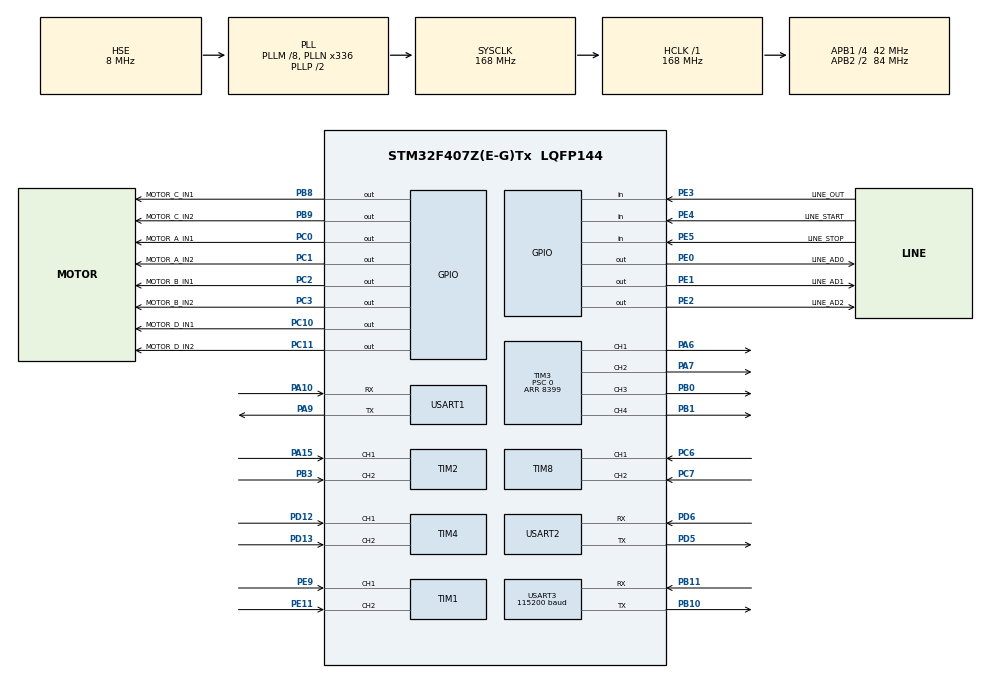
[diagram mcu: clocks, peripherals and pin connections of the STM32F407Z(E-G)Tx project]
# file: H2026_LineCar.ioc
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FREERTOS.Tasks01=controlTask,40,1024,StartControlTask,Default,NULL,Dynamic,NULL,NULL;feedbackTask,24,768,StartFeedbackTask,Default,NULL,Dynamic,NULL,NULL;imuTask,32,512,StartImuTask,Default,NULL,Dynamic,NULL,NULL
FREERTOS.configTOTAL_HEAP_SIZE=32768
FREERTOS.configUSE_NEWLIB_REENTRANT=1
Mcu.Family=STM32F4
Mcu.Name=STM32F407Z(E-G)Tx
Mcu.Package=LQFP144
NVIC.PriorityGroup=NVIC_PRIORITYGROUP_4
NVIC.TIM6_DAC_IRQn=true\:15\:0\:false\:false\:true\:false\:false\:true\:true
NVIC.TIM7_IRQn=true\:5\:0\:false\:false\:true\:true\:true\:true\:true
NVIC.TimeBase=TIM6_DAC_IRQn
NVIC.TimeBaseIP=TIM6
NVIC.USART1_IRQn=true\:6\:0\:true\:false\:true\:true\:true\:true\:true
NVIC.USART2_IRQn=true\:6\:0\:true\:false\:true\:true\:true\:true\:true
PA10.Mode=Asynchronous
PA10.Signal=USART1_RX
PA13.Mode=Serial_Wire
PA13.Signal=SYS_JTMS-SWDIO
PA14.Mode=Serial_Wire
PA14.Signal=SYS_JTCK-SWCLK
PA15.Signal=S_TIM2_CH1_ETR
PA6.Signal=S_TIM3_CH1
PA7.Signal=S_TIM3_CH2
PA9.Mode=Asynchronous
PA9.Signal=USART1_TX
PB0.Signal=S_TIM3_CH3
PB1.Signal=S_TIM3_CH4
PB3.Signal=S_TIM2_CH2
PB8.GPIO_Label=MOTOR_C_IN1
PB8.Signal=GPIO_Output
PB9.GPIO_Label=MOTOR_C_IN2
PB9.Signal=GPIO_Output
PC0.GPIO_Label=MOTOR_A_IN1
PC0.Signal=GPIO_Output
PC1.GPIO_Label=MOTOR_A_IN2
PC1.Signal=GPIO_Output
PC10.GPIO_Label=MOTOR_D_IN1
PC10.Signal=GPIO_Output
PC11.GPIO_Label=MOTOR_D_IN2
PC11.Signal=GPIO_Output
PC2.GPIO_Label=MOTOR_B_IN1
PC2.Signal=GPIO_Output
PC3.GPIO_Label=MOTOR_B_IN2
PC3.Signal=GPIO_Output
PC6.Signal=S_TIM8_CH1
PC7.Signal=S_TIM8_CH2
PD12.Signal=S_TIM4_CH1
PD13.Signal=S_TIM4_CH2
PD5.Mode=Asynchronous
PD5.Signal=USART2_TX
PD6.Mode=Asynchronous
PD6.Signal=USART2_RX
PE11.Signal=S_TIM1_CH2
PE9.Signal=S_TIM1_CH1
PH0-OSC_IN.Mode=HSE-External-Oscillator
PH0-OSC_IN.Signal=RCC_OSC_IN
PH1-OSC_OUT.Mode=HSE-External-Oscillator
PH1-OSC_OUT.Signal=RCC_OSC_OUT
ProjectManager.HeapSize=0x1000
ProjectManager.StackSize=0x1000
ProjectManager.TargetToolchain=STM32CubeIDE
RCC.48MHZClocksFreq_Value=84000000
RCC.AHBFreq_Value=168000000
RCC.APB1CLKDivider=RCC_HCLK_DIV4
RCC.APB1Freq_Value=42000000
RCC.APB1TimFreq_Value=84000000
RCC.APB2CLKDivider=RCC_HCLK_DIV2
RCC.APB2Freq_Value=84000000
RCC.APB2TimFreq_Value=168000000
RCC.CortexFreq_Value=168000000
RCC.HCLKFreq_Value=168000000
RCC.HSE_VALUE=8000000
RCC.HSI_VALUE=16000000
RCC.LSE_VALUE=32768
RCC.PLLM=8
RCC.PLLN=336
RCC.PLLSourceVirtual=RCC_PLLSOURCE_HSE
RCC.SYSCLKFreq_VALUE=168000000
RCC.SYSCLKSource=RCC_SYSCLKSOURCE_PLLCLK
RCC.VCOOutputFreq_Value=336000000
SH.S_TIM1_CH1.0=TIM1_CH1,Encoder_Interface
SH.S_TIM1_CH2.0=TIM1_CH2,Encoder_Interface
SH.S_TIM2_CH1_ETR.0=TIM2_CH1,Encoder_Interface
SH.S_TIM2_CH2.0=TIM2_CH2,Encoder_Interface
SH.S_TIM3_CH1.0=TIM3_CH1,PWM Generation1 CH1
SH.S_TIM3_CH2.0=TIM3_CH2,PWM Generation2 CH2
SH.S_TIM3_CH3.0=TIM3_CH3,PWM Generation3 CH3
SH.S_TIM3_CH4.0=TIM3_CH4,PWM Generation4 CH4
SH.S_TIM4_CH1.0=TIM4_CH1,Encoder_Interface
SH.S_TIM4_CH2.0=TIM4_CH2,Encoder_Interface
SH.S_TIM8_CH1.0=TIM8_CH1,Encoder_Interface
SH.S_TIM8_CH2.0=TIM8_CH2,Encoder_Interface
TIM1.EncoderMode=TIM_ENCODERMODE_TI12
TIM1.IC1Filter=10
TIM1.IC2Filter=10
TIM2.EncoderMode=TIM_ENCODERMODE_TI12
TIM2.IC1Filter=10
TIM2.IC2Filter=10
TIM3.AutoReloadPreload=TIM_AUTORELOAD_PRELOAD_ENABLE
TIM3.Channel-PWM\ Generation1\ CH1=TIM_CHANNEL_1
TIM3.Channel-PWM\ Generation2\ CH2=TIM_CHANNEL_2
TIM3.Channel-PWM\ Generation3\ CH3=TIM_CHANNEL_3
TIM3.Channel-PWM\ Generation4\ CH4=TIM_CHANNEL_4
TIM3.Period=8399
TIM3.Prescaler=0
TIM4.EncoderMode=TIM_ENCODERMODE_TI12
TIM4.IC1Filter=10
TIM4.IC2Filter=10
TIM7.Period=99
TIM7.Prescaler=8399
TIM8.EncoderMode=TIM_ENCODERMODE_TI12
TIM8.IC1Filter=10
TIM8.IC2Filter=10
USART1.VirtualMode=VM_ASYNC
USART2.VirtualMode=VM_ASYNC
VP_FREERTOS_VS_CMSIS_V2.Mode=CMSIS_V2
VP_SYS_VS_tim6.Mode=TIM6
VP_TIM3_VS_ClockSourceINT.Mode=Internal
VP_TIM7_VS_ClockSourceINT.Mode=Enable_Timer
board=custom
PB10.Mode=Asynchronous
PB10.Signal=USART3_TX
PB11.Mode=Asynchronous
PB11.Signal=USART3_RX
PB10.GPIO_PuPd=GPIO_PULLUP
PB11.GPIO_PuPd=GPIO_PULLUP
USART3.BaudRate=115200
USART3.VirtualMode=VM_ASYNC
Dma.Request0=USART3_RX
Dma.USART3_RX.0.Instance=DMA1_Stream1
Dma.USART3_RX.0.Direction=DMA_PERIPH_TO_MEMORY
Dma.USART3_RX.0.PeriphInc=DMA_PINC_DISABLE
Dma.USART3_RX.0.MemInc=DMA_MINC_ENABLE
Dma.USART3_RX.0.PeriphDataAlignment=DMA_PDATAALIGN_BYTE
Dma.USART3_RX.0.MemDataAlignment=DMA_MDATAALIGN_BYTE
Dma.USART3_RX.0.Mode=DMA_CIRCULAR
Dma.USART3_RX.0.Priority=DMA_PRIORITY_HIGH
Dma.USART3_RX.0.FIFOMode=DMA_FIFOMODE_DISABLE
NVIC.USART3_IRQn=true\:6\:0\:true\:false\:true\:true\:true\:true\:true
NVIC.DMA1_Stream1_IRQn=true\:6\:0\:true\:false\:true\:false\:true\:true\:true
PE0.GPIO_Label=LINE_AD0
PE0.Signal=GPIO_Output
PE1.GPIO_Label=LINE_AD1
PE1.Signal=GPIO_Output
PE2.GPIO_Label=LINE_AD2
PE2.Signal=GPIO_Output
PE3.GPIO_Label=LINE_OUT
PE3.Signal=GPIO_Input
PE4.GPIO_Label=LINE_START
PE4.Signal=GPIO_Input
PE4.GPIO_PuPd=GPIO_PULLUP
PE5.GPIO_Label=LINE_STOP
PE5.Signal=GPIO_Input
PE5.GPIO_PuPd=GPIO_PULLUP

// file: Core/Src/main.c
/* USER CODE BEGIN Header */
/**
  ******************************************************************************
  * @file           : main.c
  * @brief          : Main program body
  ******************************************************************************
  * @attention
  *
  * Copyright (c) 2026 STMicroelectronics.
  * All rights reserved.
  *
  * This software is licensed under terms that can be found in the LICENSE file
  * in the root directory of this software component.
  * If no LICENSE file comes with this software, it is provided AS-IS.
  *
  ******************************************************************************
  */
/* USER CODE END Header */
#include "main.h"
#include "cmsis_os.h"
#include "tim.h"
#include "usart.h"
#include "gpio.h"

/* USER CODE BEGIN Includes */
#include "chassis_control.h"

/* USER CODE END Includes */

void SystemClock_Config(void);
void MX_FREERTOS_Init(void);

int main(void)
{

  /* MCU Configuration--------------------------------------------------------*/

  /* Reset of all peripherals, Initializes the Flash interface and the Systick. */
  HAL_Init();

  /* Configure the system clock */
  SystemClock_Config();

  /* Initialize all configured peripherals */
  MX_GPIO_Init();
  MX_TIM3_Init();
  MX_USART1_UART_Init();
  MX_TIM1_Init();
  MX_TIM2_Init();
  MX_TIM4_Init();
  MX_TIM7_Init();
  MX_TIM8_Init();
  MX_USART2_UART_Init();
  MX_USART3_UART_Init();

  /* Init scheduler */
  osKernelInitialize();  /* Call init function for freertos objects (in cmsis_os2.c) */
  MX_FREERTOS_Init();

  /* Start scheduler */
  osKernelStart();

  /* We should never get here as control is now taken by the scheduler */

  /* Infinite loop */
  while (1)
  {

  }
}

void SystemClock_Config(void)
{
  RCC_OscInitTypeDef RCC_OscInitStruct = {0};
  RCC_ClkInitTypeDef RCC_ClkInitStruct = {0};

  /** Configure the main internal regulator output voltage
  */
  __HAL_RCC_PWR_CLK_ENABLE();
  __HAL_PWR_VOLTAGESCALING_CONFIG(PWR_REGULATOR_VOLTAGE_SCALE1);

  /** Initializes the RCC Oscillators according to the specified parameters
  * in the RCC_OscInitTypeDef structure.
  */
  RCC_OscInitStruct.OscillatorType = RCC_OSCILLATORTYPE_HSE;
  RCC_OscInitStruct.HSEState = RCC_HSE_ON;
  RCC_OscInitStruct.PLL.PLLState = RCC_PLL_ON;
  RCC_OscInitStruct.PLL.PLLSource = RCC_PLLSOURCE_HSE;
  RCC_OscInitStruct.PLL.PLLM = 8;
  RCC_OscInitStruct.PLL.PLLN = 336;
  RCC_OscInitStruct.PLL.PLLP = RCC_PLLP_DIV2;
  RCC_OscInitStruct.PLL.PLLQ = 4;
  if (HAL_RCC_OscConfig(&RCC_OscInitStruct) != HAL_OK)
  {
    Error_Handler();
  }

  /** Initializes the CPU, AHB and APB buses clocks
  */
  RCC_ClkInitStruct.ClockType = RCC_CLOCKTYPE_HCLK|RCC_CLOCKTYPE_SYSCLK
                              |RCC_CLOCKTYPE_PCLK1|RCC_CLOCKTYPE_PCLK2;
  RCC_ClkInitStruct.SYSCLKSource = RCC_SYSCLKSOURCE_PLLCLK;
  RCC_ClkInitStruct.AHBCLKDivider = RCC_SYSCLK_DIV1;
  RCC_ClkInitStruct.APB1CLKDivider = RCC_HCLK_DIV4;
  RCC_ClkInitStruct.APB2CLKDivider = RCC_HCLK_DIV2;

  if (HAL_RCC_ClockConfig(&RCC_ClkInitStruct, FLASH_LATENCY_5) != HAL_OK)
  {
    Error_Handler();
  }
}

void HAL_TIM_PeriodElapsedCallback(TIM_HandleTypeDef *htim)
{
  if (htim->Instance == TIM6)
  {
    HAL_IncTick();
  }
  /* USER CODE BEGIN Callback 1 */

  if (htim->Instance == TIM7)
  {
    Chassis_ControlPeriodElapsedCallback();
  }

  /* USER CODE END Callback 1 */
}

void Error_Handler(void)
{
  __disable_irq();
  while (1)
  {
  }
}

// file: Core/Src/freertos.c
/* H2026 line-following application. The control task exclusively owns motion. */
#include "FreeRTOS.h"
#include "task.h"
#include "main.h"
#include "cmsis_os.h"
#include "chassis_control.h"
#include "line_app.h"
#include "encoder.h"
#include "control_timing.h"
#include "runtime_diagnostics.h"
#include "jy901s.h"
#include "Vofa.h"

#define CONTROL_FLAG_ENCODER_SAMPLE (1UL << 0)
RuntimeDiagnostics g_runtime_diagnostics;
static Vofa_HandleTypedef s_vofa;
osThreadId_t controlTaskHandle, feedbackTaskHandle, imuTaskHandle;
static void StartControlTask(void *argument);
static void StartFeedbackTask(void *argument);
static void StartImuTask(void *argument);
static const osThreadAttr_t control_attributes={.name="controlTask",.stack_size=4096,.priority=osPriorityHigh};
static const osThreadAttr_t feedback_attributes={.name="feedbackTask",.stack_size=3072,.priority=osPriorityNormal};
static const osThreadAttr_t imu_attributes={.name="imuTask",.stack_size=2048,.priority=osPriorityAboveNormal};

void MX_FREERTOS_Init(void)
{
  Vofa_Init(&s_vofa,VOFA_MODE_SKIP);
  VofaPort_Init();
  controlTaskHandle=osThreadNew(StartControlTask,NULL,&control_attributes);
  feedbackTaskHandle=osThreadNew(StartFeedbackTask,NULL,&feedback_attributes);
  imuTaskHandle=osThreadNew(StartImuTask,NULL,&imu_attributes);
  if (!controlTaskHandle || !feedbackTaskHandle || !imuTaskHandle) Error_Handler();
}

static void StartControlTask(void *argument)
{
  (void)argument;
  ControlTiming timing={0};
  CoreDebug->DEMCR|=CoreDebug_DEMCR_TRCENA_Msk;
  DWT->CTRL|=DWT_CTRL_CYCCNTENA_Msk;
  if (Chassis_Init()!=HAL_OK) Error_Handler();
  LineApp_Init();
  for (;;) {
    uint32_t flags=osThreadFlagsWait(CONTROL_FLAG_ENCODER_SAMPLE,osFlagsWaitAny,osWaitForever);
    if ((flags & osFlagsError)!=0U) continue;
    uint32_t start=HAL_GetTick(), cycles=DWT->CYCCNT;
    ControlTimingResult result=ControlTiming_Update(&timing,g_runtime_diagnostics.control_events,start);
    if (result==CONTROL_TIMING_NONE) continue;
    g_runtime_diagnostics.max_interval_ms=timing.max_interval;
    g_runtime_diagnostics.missed_events=timing.missed_events;
    g_runtime_diagnostics.late_wakes=timing.late_wakes;
    if (result==CONTROL_TIMING_FAULT) {
      LineApp_Fault(LINE_TIMING_FAULT);
      Chassis_StopWithReason(CHASSIS_STOP_CONTROL_TIMING);
      Encoder_Reset();
    } else {
      LineApp_Step();
      Chassis_ControlStep();
      ++g_runtime_diagnostics.control_runs;
    }
    uint32_t us=(DWT->CYCCNT-cycles)/(SystemCoreClock/1000000U);
    if (us>g_runtime_diagnostics.max_execution_us) g_runtime_diagnostics.max_execution_us=us;
    uint32_t ms=HAL_GetTick()-start;
    if (ms>g_runtime_diagnostics.max_execution_ms) g_runtime_diagnostics.max_execution_ms=ms;
  }
}

static void StartFeedbackTask(void *argument)
{
  (void)argument;
  for (;;) {
    ChassisFeedback f;
    JY901S_Feedback imu;
    LineFeedback line;
    Chassis_GetFeedback(&f);
    JY901S_GetFeedback(&imu);
    LineApp_GetFeedback(&line);
    ++g_runtime_diagnostics.telemetry_sequence;
    g_runtime_diagnostics.telemetry_sample_ms=HAL_GetTick();
    g_runtime_diagnostics.stack_free_min[0]=osThreadGetStackSpace(controlTaskHandle);
    g_runtime_diagnostics.stack_free_min[3]=osThreadGetStackSpace(feedbackTaskHandle);
    g_runtime_diagnostics.stack_free_min[4]=osThreadGetStackSpace(imuTaskHandle);
    /* Channels 1..33 retain their order; 34..36 capture short invalid-line events. */
    Vofa_Printf(&s_vofa,
      "%d,%d,%d,%d,%d,%d,%d,%d,%d,%d,%d,%d,%ld,%ld,%ld,%ld,%u,%u,%u,%lu,%u,%u,%u,%u,%ld,%ld,%lu,%ld,%u,%u,%ld,%u,%lu,%u,%lu,%u\r\n",
      f.target_mm_s[0],f.target_mm_s[1],f.target_mm_s[2],f.target_mm_s[3],
      f.measured_mm_s[0],f.measured_mm_s[1],f.measured_mm_s[2],f.measured_mm_s[3],
      f.pwm[0],f.pwm[1],f.pwm[2],f.pwm[3],
      (long)(f.heading_target_deg*100),(long)(f.heading_measured_deg*100),
      (long)(imu.yaw_rate_dps*100),(long)(f.heading_output_dps*100),
      (unsigned)imu.status,(unsigned)imu.calibration_samples,(unsigned)f.heading_active,(unsigned long)imu.error_count,
      (unsigned)line.sample.raw,(unsigned)line.sample.mask,(unsigned)line.controller.state,
      (unsigned)line.controller.fault,(long)(line.sample.error*1000),
      (long)line.controller.travel_mm,(unsigned long)line.controller.elapsed_ms,
      (long)(line.controller.turned_deg*100),(unsigned)line.config.armed,(unsigned)Chassis_IsStopped(),
      (long)line.output.speed_mm_s,(unsigned)imu.fault_reason,(unsigned long)imu.uart_error,
      (unsigned)line.controller.speed_reason,(unsigned long)line.controller.invalid_events,
      (unsigned)line.controller.last_invalid_mask);
    uint32_t delay=(Chassis_GetTelemetryPeriodMs()*osKernelGetTickFreq()+999U)/1000U;
    osDelay(delay ? delay : 1U);
  }
}

static void StartImuTask(void *argument)
{
  (void)argument;
  JY901S_Feedback imu;
  const uint32_t period=(osKernelGetTickFreq()+199U)/200U;
  for (;;) {
    if (JY901S_Init()==HAL_OK) {
      uint32_t next=osKernelGetTickCount();
      for (;;) {
        JY901S_Poll();
        JY901S_GetFeedback(&imu);
        if (imu.status==JY901S_FAULT) break;
        next+=period;
        if ((int32_t)(next-osKernelGetTickCount())<=0) next=osKernelGetTickCount()+period;
        (void)osDelayUntil(next);
      }
    }
    /* Control owner observes stale IMU and latches the stop on the next 10 ms step. */
    osDelay(osKernelGetTickFreq());
  }
}

void Chassis_ControlPeriodElapsedCallback(void)
{
  if (controlTaskHandle!=NULL) {
    ++g_runtime_diagnostics.control_events;
    (void)osThreadFlagsSet(controlTaskHandle,CONTROL_FLAG_ENCODER_SAMPLE);
  }
}
